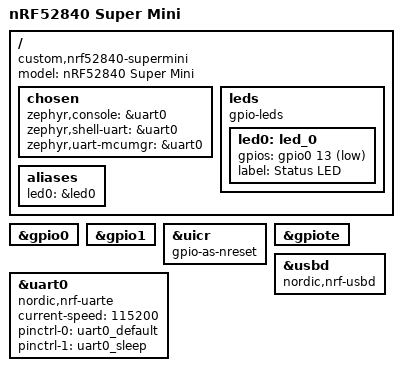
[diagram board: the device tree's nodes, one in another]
/* SPDX-License-Identifier: Apache-2.0 */

/dts-v1/;
#include <nordic/nrf52840_qiaa.dtsi>
#include <nordic/nrf52840_partition.dtsi>
#include "nrf52840_supermini-pinctrl.dtsi"

/ {
    model = "nRF52840 Super Mini";
    compatible = "custom,nrf52840-supermini";

    chosen {
        zephyr,console = &uart0;
        zephyr,shell-uart = &uart0;
        zephyr,uart-mcumgr = &uart0;
    };

    leds {
        compatible = "gpio-leds";

        /* Common Super Mini status LED. Change this pin if your board differs. */
        led0: led_0 {
            gpios = <&gpio0 13 GPIO_ACTIVE_LOW>;
            label = "Status LED";
        };
    };

    aliases {
        led0 = &led0;
    };
};

&gpio0 {
    status = "okay";
};

&gpio1 {
    status = "okay";
};

&uicr {
    gpio-as-nreset;
};

&gpiote {
    status = "okay";
};

&uart0 {
    compatible = "nordic,nrf-uarte";
    status = "okay";
    current-speed = <115200>;
    pinctrl-0 = <&uart0_default>;
    pinctrl-1 = <&uart0_sleep>;
    pinctrl-names = "default", "sleep";
};

&usbd {
    compatible = "nordic,nrf-usbd";
    status = "okay";
};
